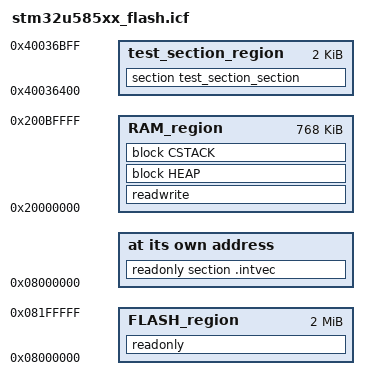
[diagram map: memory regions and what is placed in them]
/**********************************************************************************/
//*###ICF### Section handled by ICF editor, don't touch! ****/
/*-Editor annotation file-*/
/* IcfEditorFile="$TOOLKIT_DIR$\config\ide\IcfEditor\cortex_v1_0.xml" *//*-Specials-*/

/**********************************************************************************/

/*-Sizes-*/
define symbol __ICFEDIT_intvec_start__ = 0x08000000;

define symbol __ICFEDIT_size_cstack__ = 0x400;
define symbol __ICFEDIT_size_heap__  = 0x200;


/*-Memory Regions-*/
define symbol __ICFEDIT_region_RAM_start__          = 0x20000000;
define symbol __ICFEDIT_region_RAM_end__            = 0x200BFFFF;
define symbol __ICFEDIT_region_FLASH_start__        = 0x08000000;
define symbol __ICFEDIT_region_FLASH_end__          = 0x81FFFFF;
define symbol __ICFEDIT_region_test_section_start__ = 0x40036400;
define symbol __ICFEDIT_region_test_section_end__   = 0x40036BFF;
/**** End of ICF editor section. ###ICF###*/

define memory mem with size = 4G;
define region RAM_region          = mem:[from __ICFEDIT_region_RAM_start__          to __ICFEDIT_region_RAM_end__];
define region FLASH_region        = mem:[from __ICFEDIT_region_FLASH_start__        to __ICFEDIT_region_FLASH_end__];
define region test_section_region = mem:[from __ICFEDIT_region_test_section_start__ to __ICFEDIT_region_test_section_end__];

/*-Blocks-*/
define block CSTACK with alignment = 8, size = __ICFEDIT_size_cstack__ {};
define block HEAP   with alignment = 8, size = __ICFEDIT_size_heap__  {};

/*-Initialization strategies-*/
initialize by copy { readwrite };
do not initialize  { section .noinit };

/*-Sections placements-*/
place at address mem:__ICFEDIT_intvec_start__ { readonly section .intvec };

place in test_section_region  { section test_section_section };
place in FLASH_region  { readonly };
place in RAM_region  { readwrite, block HEAP, block CSTACK };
